# CY8C4245AXI_483 register map
File version: 0.1
PSoC 4200
Registers are 32-bit, read-write, no defined reset value unless marked. A register's access mark holds for its fields unless they carry their own. Offsets are from the block's base; lines under a group give offsets from that group; [hi:lo] are bit positions; {n}, {i} and the like mark numbered series; 'fields as' and 'values as' point back to an identical list; <NAME> marks a mode.

## Memory map
0x00000000 UART — Serial Communication Block
0x00000000 SPIS_1
0x00000000 CSD_IDAC1 — IDAC
0x00000000 CSD_IDAC2 — IDAC
0x00000000 PWM_4
0x00000000 PWM_1
0x00000000 PWM_2
0x00000000 PWM_3
0x00000000 SPI — Serial Communication Block

## SPIS_1
Base 0x00000000
0x400F0000 SPIS_1_RX_DATA 8-bit — SPIS RX Data
0x400F0000 SPIS_1_TX_DATA 8-bit — SPIS TX Data
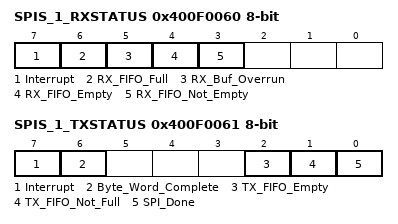
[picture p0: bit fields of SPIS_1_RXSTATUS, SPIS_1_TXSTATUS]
0x400F0060 SPIS_1_RXSTATUS 8-bit — SPIS RX Status Register
  [7] Interrupt ro — Set when interrupt occurs
  [6] RX_FIFO_Full ro — Set when the RX Data FIFO is full
  [5] RX_Buf_Overrun ro — Set when RX Data has overrun the 4 byte/word FIFO without being moved to the RX buffer cmemory array (if one exists)
  [4] RX_FIFO_Empty ro — Set when the RX Data FIFO is empty
  [3] RX_FIFO_Not_Empty ro — Set when the RX Data FIFO is not empty. That is, at least one byte/word is in the RX FIFO
0x400F0061 SPIS_1_TXSTATUS 8-bit — SPIS TX Status Register
  [7] Interrupt ro — Set when interrupt occurs
  [6] Byte_Word_Complete ro — Set when a byte/word transmit has completed
  [2] TX_FIFO_Empty ro — Set when the TX Data FIFO is empty
  [1] TX_FIFO_Not_Full ro — Set when the TX Data FIFO is not full
  [0] SPI_Done ro — Set when all of the data in the transmit FIFO has been sent. Set when Byte/Word Complete has been set and TX Data FIFO is empty

## CSD_IDAC1 — IDAC
Base 0x00000000
Same registers: CSD_IDAC2 0x00000000
0x40080004 CSD_IDAC_POLARITY
0x40080008 CSD_IDAC
0x4008FF00 CSD_TRIM1 — CSD IDAC TRIM1
0x4008FF04 CSD_TRIM2 — CSD IDAC TRIM2

## PWM_4
Base 0x00000000
0x40050108 COUNTER — Current counter value
0x4005010C CC — Compare / capture value
0x40050110 CC_BUF — Compare / capture buffer value
0x40050114 PERIOD — Period value
0x40050118 PERIOD_BUF — Period buffer value

## PWM_1
Base 0x00000000
0x40050148 COUNTER — Current counter value
0x4005014C CC — Compare / capture value
0x40050150 CC_BUF — Compare / capture buffer value
0x40050154 PERIOD — Period value
0x40050158 PERIOD_BUF — Period buffer value

## PWM_2
Base 0x00000000
0x40050188 COUNTER — Current counter value
0x4005018C CC — Compare / capture value
0x40050190 CC_BUF — Compare / capture buffer value
0x40050194 PERIOD — Period value
0x40050198 PERIOD_BUF — Period buffer value

## PWM_3
Base 0x00000000
0x400501C8 COUNTER — Current counter value
0x400501CC CC — Compare / capture value
0x400501D0 CC_BUF — Compare / capture buffer value
0x400501D4 PERIOD — Period value
0x400501D8 PERIOD_BUF — Period buffer value
